# I94100_v1_3 register map
File version: 1.0
Registers are 32-bit, read-write, reset 0x0 unless marked. A register's access mark holds for its fields unless they carry their own. Offsets are from the block's base; [hi:lo] are bit positions; lines under a group give offsets from that group; {n}, {i} and the like mark numbered series; 'fields as' and 'values as' point back to an identical list.

## PWM0 — PWM Register Map
Base 0x40058000
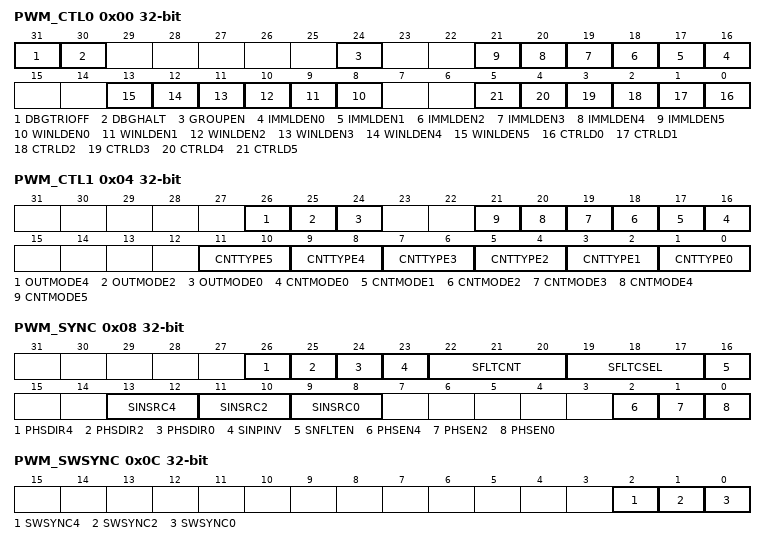
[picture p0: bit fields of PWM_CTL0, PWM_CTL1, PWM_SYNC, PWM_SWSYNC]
0x00 PWM_CTL0 — PWM Control Register 0
  [31] DBGTRIOFF — ICE Debug Mode Acknowledge Disable (Write Protected). PWM pin will keep output no matter ICE debug mode acknowledged or not. Note: This register is write protected. Refer to SYS_REGLCTL register.
    0=ICE debug mode acknowledgement effects PWM output; 1=ICE debug mode acknowledgement disabled
  [30] DBGHALT — ICE Debug Mode Counter Halt (Write Protected). If counter halt is enabled, PWM all counters will keep current value until exit ICE debug mode. Note: This register is write protected. Refer to SYS_REGLCTL register.
    0=ICE debug mode counter halt disable; 1=ICE debug mode counter halt enable
  [24] GROUPEN — Group Function Enable Bit(S)
    0=The output waveform of each PWM channel are independent; 1=Unify the PWM_CH2 and PWM_CH4 to output the same waveform as PWM_CH0 and unify the PWM_CH3 and PWM_CH5 to output the same waveform as PWM_CH1
  [n+16] IMMLDEN{n} (n=0..5) — PWM Channel {n} Immediately Load Enable Bits. Note: If IMMLDEN{n} is enabled, WINLDEN{n} and CTRLD{n} will be invalid.
    0=PERIOD will load to PBUF at the end point of each period. CMPDAT will load to CMPBUF at the end point or center point of each period by setting CTRLD bit; 1=PERIOD/CMPDAT will load to PBUF and CMPBUF immediately when software update PERIOD/CMPDAT
  [n+8] WINLDEN{n} (n=0..5) — PWM Channel {n} Window Load Enable Bits
    0=PERIOD will load to PBUF at the end point of each period. CMPDAT will load to CMPBUF at the end point or center point of each period by setting CTRLD bit; 1=PERIOD will load to PBUF at the end point of each period. CMPDAT will load to CMPBUF at the end point of each period when valid reload window is set. The valid reload window is set by software write 1 to PWM_LOAD register and cleared by hardware after load success
  [n] CTRLD{n} (n=0..5) — PWM Channel {n} Center Re-load. In up-down counter type, PERIOD will load to PBUF at the end point of each period. CMPDAT will load to CMPBUF at the center point of a period.
0x04 PWM_CTL1 — PWM Control Register 1
  [26] OUTMODE4 — PWM Channel 4 Output Mode. Note: When operating in group function, these bits must all set to the same mode.
    0=PWM independent mode; 1=PWM complementary mode
  [25] OUTMODE2 — PWM Channel 2 Output Mode. Note: When operating in group function, these bits must all set to the same mode.
    0=PWM independent mode; 1=PWM complementary mode
  [24] OUTMODE0 — PWM Channel 0 Output Mode. Note: When operating in group function, these bits must all set to the same mode.
    0=PWM independent mode; 1=PWM complementary mode
  [n+16] CNTMODE{n} (n=0..5) — PWM Channel {n} Counter Mode
    0=Auto-reload mode; 1=One-shot mode
  [2n+1:2n] CNTTYPE{n} (n=0..5) — PWM Channel {n} Counter Behavior Type
    0=Up counter type (supports in capture mode); 1=Down count type (supports in capture mode); 2=Up-down counter type; 3=Reserved. Do not use
0x08 PWM_SYNC — PWM Synchronization Register
  [26] PHSDIR4 — PWM Channel 4 Phase Direction Control
    0=Control PWM counter count decrement after synchronizing; 1=Control PWM counter count increment after synchronizing
  [25] PHSDIR2 — PWM Channel 2 Phase Direction Control
    values as PHSDIR4
  [24] PHSDIR0 — PWM Channel 0 Phase Direction Control
    values as PHSDIR4
  [23] SINPINV — SYNC Input Pin Inverse
    0=The state of pin SYNC is passed to the negative edge detector; 1=The inversed state of pin SYNC is passed to the negative edge detector
  [22:20] SFLTCNT — SYNC Edge Detector Filter Count. The register bits control the counter number of edge detector.
  [19:17] SFLTCSEL — SYNC Edge Detector Filter Clock Selection
    0=Filter clock = HCLK; 1=Filter clock = HCLK/2; 2=Filter clock = HCLK/4; 3=Filter clock = HCLK/8; 4=Filter clock = HCLK/16; 5=Filter clock = HCLK/32; 6=Filter clock = HCLK/64; 7=Filter clock = HCLK/128
  [16] SNFLTEN — PWM0_SYNC_IN Noise Filter Enable Bits
    0=Noise filter of input pin PWM0_SYNC_IN is Disabled; 1=Noise filter of input pin PWM0_SYNC_IN is Enabled
  [13:12] SINSRC4 — PWM Channel 4 PWM0_SYNC_IN Source Selection
    0=Synchronize source from SYNC_IN or SWSYNC; 1=Counter equal to 0; 2=Counter equal to PWM_CMPDATm, m denotes 1, 3, 5; 3=SYNC_OUT will not be generated
  [11:10] SINSRC2 — PWM Channel 2 PWM0_SYNC_IN Source Selection
    values as SINSRC4
  [9:8] SINSRC0 — PWM Channel 0 PWM0_SYNC_IN Source Selection
    values as SINSRC4
  [2] PHSEN4 — PWM Channel 4 SYNC Phase Enable Bits
    0=PWM counter disable to load PHS value; 1=PWM counter enable to load PHS value
  [1] PHSEN2 — PWM Channel 2 SYNC Phase Enable Bits
    values as PHSEN4
  [0] PHSEN0 — PWM Channel 0 SYNC Phase Enable Bits
    values as PHSEN4
0x0C PWM_SWSYNC — PWM Software Control Synchronization Register
  [2] SWSYNC4 — PWM Channel 4 Software SYNC Function. When SINSRC4 (PWM_SYNC[13:12]) is selected to 0, SYNC_OUT source is come from SYNC_IN or this bit.
  [1] SWSYNC2 — PWM Channel 2 Software SYNC Function. When SINSRC2 (PWM_SYNC[11:10]) is selected to 0, SYNC_OUT source is come from SYNC_IN or this bit.
  [0] SWSYNC0 — PWM Channel 0 Software SYNC Function. When SINSRC0 (PWM_SYNC[9:8]) is selected to 0, SYNC_OUT source is come from SYNC_IN or this bit.
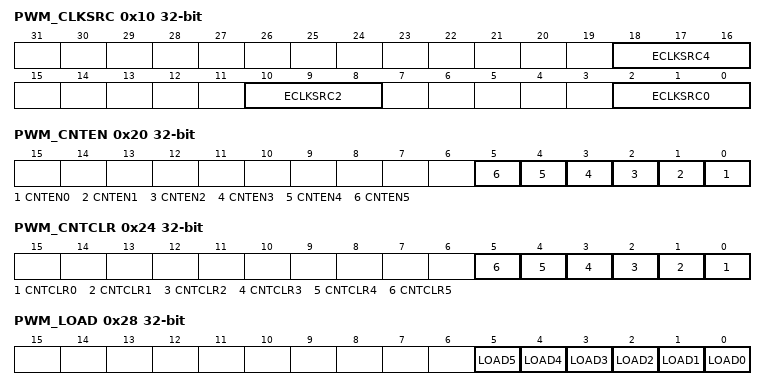
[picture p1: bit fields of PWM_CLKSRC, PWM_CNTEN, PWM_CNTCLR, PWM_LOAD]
0x10 PWM_CLKSRC — PWM Clock Source Register
  [all] fields
    0=PWM0_CLK; {v}=TIMER{v-1} overflow (v=1..4)
  [18:16] ECLKSRC4 — PWM_CH45 External Clock Source Select
  [10:8] ECLKSRC2 — PWM_CH23 External Clock Source Select
  [2:0] ECLKSRC0 — PWM_CH01 External Clock Source Select
0x14 PWM_CLKPSC0_1 — PWM Clock Pre-scale Register 0/1
  [11:0] CLKPSC — PWM Counter Clock Pre-scale. The clock of PWM counter is decided by clock prescaler. Each PWM pair share one PWM counter clock prescaler. The clock of PWM counter is divided by (CLKPSC+ 1).
0x18 PWM_CLKPSC2_3 — PWM Clock Pre-scale Register 2/3
  fields as PWM_CLKPSC0_1
0x1C PWM_CLKPSC4_5 — PWM Clock Pre-scale Register 4/5
  fields as PWM_CLKPSC0_1
0x20 PWM_CNTEN — PWM Counter Enable Register
  [all] fields
    0=PWM Counter and clock prescaler Stop Running; 1=PWM Counter and clock prescaler Start Running
  [n] CNTEN{n} (n=0..5) — PWM Channel {n} Counter Enable Bits
0x24 PWM_CNTCLR — PWM Clear Counter Register
  [all] fields
    0=No effect; 1=Clear 16-bit PWM counter to 0000H
  [n] CNTCLR{n} (n=0..5) — PWM Channel {n} Clear PWM Counter Control Bit. It is automatically cleared by hardware.
0x28 PWM_LOAD
  [all] fields
    0=No effect. No load window is set; 1=Set load window of window loading mode. Load window is set
  [n] LOAD{n} (n=0..5) — PWM Channel {n} Re-load PWM Comparator Register (CMPDAT) Control Bit. This bit is software write, hardware clear when current PWM period end. Write Operation:
{0x30+4i} PWM_PERIOD{i} (i=0..5) — PWM Period Register {i}
  [15:0] PERIOD — PWM Period Register. Up-Count mode: In this mode, PWM counter counts from 0 to PERIOD, and restarts from 0. Down-Count mode: In this mode, PWM counter counts from PERIOD to 0, and restarts from PERIOD.
{0x50+4i} PWM_CMPDAT{i} (i=0..5) — PWM Comparator Register {i}
  [15:0] CMP — PWM Comparator Register. CMP use to compare with CNTR to generate PWM waveform, interrupt and trigger EADC. In independent mode, CMPDAT0~5 denote as 6 independent PWM_CH0~5 compared point. In complementary mode, CMPDAT0, 2, 4 denote as first compared point, and CMPDAT1, 3, 5 denote as second compared point for the corresponding 3 complementary pairs PWM_CH0 and PWM_CH1, PWM_CH2 and PWM_CH3, PWM_CH4 and PWM_CH5.
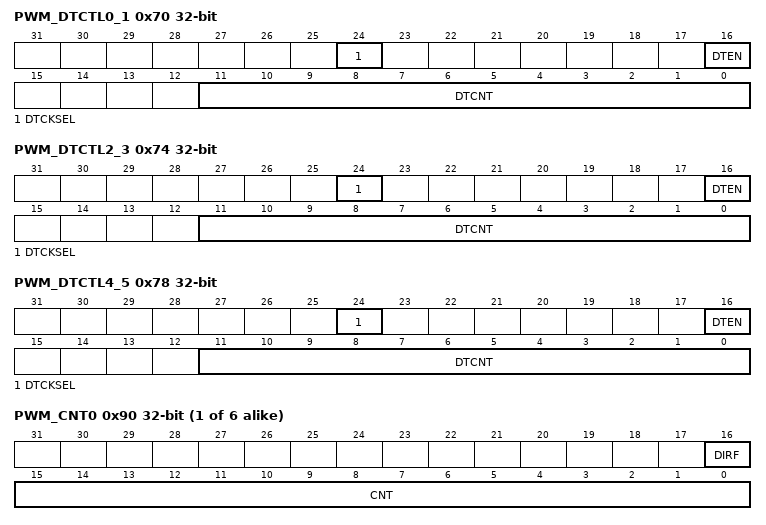
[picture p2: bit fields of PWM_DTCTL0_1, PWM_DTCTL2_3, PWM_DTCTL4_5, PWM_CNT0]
0x70 PWM_DTCTL0_1 — PWM Dead-time Control Register 0/1
  [24] DTCKSEL — Dead-time Clock Select (Write Protected). Note: This register is write protected. Refer to SYS_REGLCTL register.
    0=Dead-time clock source from PWM_CLK; 1=Dead-time clock source from prescaler output
  [16] DTEN — Enable Dead-time Insertion for PWM Pair (PWM_CH0, PWM_CH1) (PWM_CH2, PWM_CH3) (PWM_CH4, PWM_CH5) (Write Protected). Dead-time insertion is only active when this pair of complementary PWM is enabled. If dead- time insertion is inactive, the outputs of pin pair are complementary without any delay. Note: This register is write protected. Refer to SYS_REGLCTL register.
    0=Dead-time insertion Disabled on the pin pair; 1=Dead-time insertion Enabled on the pin pair
  [11:0] DTCNT — Dead-time Counter (Write Protected). The dead-time can be calculated from the following formula: Note: This register is write protected. Refer to SYS_REGLCTL register.
0x74 PWM_DTCTL2_3 — PWM Dead-time Control Register 2/3
  fields as PWM_DTCTL0_1
0x78 PWM_DTCTL4_5 — PWM Dead-time Control Register 4/5
  fields as PWM_DTCTL0_1
0x80 PWM_PHS0_1 — PWM Counter Phase Register 0/1
  [15:0] PHS — PWM Synchronous Start Phase Bits. PHS determines the PWM synchronous start phase value. These bits only use in synchronous function.
0x84 PWM_PHS2_3 — PWM Counter Phase Register 2/3
  fields as PWM_PHS0_1
0x88 PWM_PHS4_5 — PWM Counter Phase Register 4/5
  fields as PWM_PHS0_1
{0x90+4i} PWM_CNT{i} ro (i=0..5) — PWM Counter Register {i}
  [16] DIRF — PWM Direction Indicator Flag (Read Only)
    0=Counter is Down count; 1=Counter is UP count
  [15:0] CNT — PWM Data Register (Read Only). User can monitor CNTR to know the current value in 16-bit period counter.
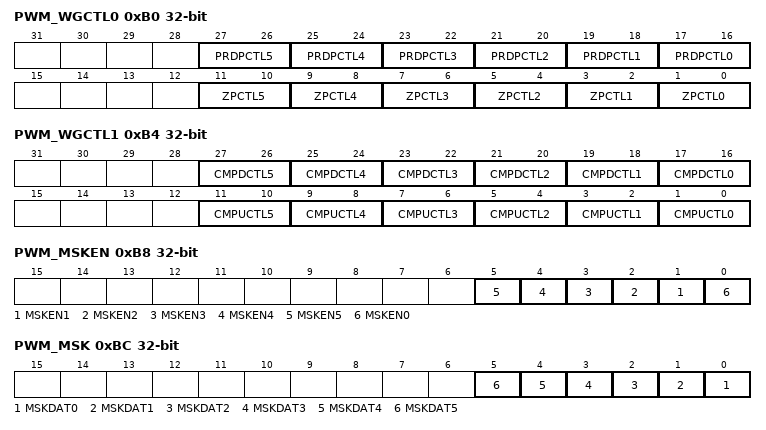
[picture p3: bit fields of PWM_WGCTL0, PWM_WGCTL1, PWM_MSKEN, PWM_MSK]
0xB0 PWM_WGCTL0 — PWM Generation Register 0
  [2n+17:2n+16] PRDPCTL{n} (n=0..5) — PWM Channel {n} Period (Center) Point Control. PWM can control output level when PWM counter count to (PERIODn+1). Note: This bit is center point control when PWM counter operating in up-down counter type.
    0=Do nothing; 1=PWM period (center) point output Low; 2=PWM period (center) point output High; 3=PWM period (center) point output Toggle
  [2n+1:2n] ZPCTL{n} (n=0..5) — PWM Channel {n} Zero Point Control. PWM can control output level when PWM counter count to zero.
    0=Do nothing; 1=PWM zero point output Low; 2=PWM zero point output High; 3=PWM zero point output Toggle
0xB4 PWM_WGCTL1 — PWM Generation Register 1
  [2n+17:2n+16] CMPDCTL{n} (n=0..5) — PWM Channel {n} Compare Down Point Control. PWM can control output level when PWM counter down count to CMPDAT. Note: In complementary mode, CMPDCTL1, 3, 5 use as another CMPDCTL for channel 0, 2, 4.
    0=Do nothing; 1=PWM compare down point output Low; 2=PWM compare down point output High; 3=PWM compare down point output Toggle
  [2n+1:2n] CMPUCTL{n} (n=0..5) — PWM Channel {n} Compare Up Point Control. PWM can control output level when PWM counter up count to CMPDAT. Note: In complementary mode, CMPUCTL1, 3, 5 use as another CMPUCTL for channel 0, 2, 4.
    0=Do nothing; 1=PWM compare up point output Low; 2=PWM compare up point output High; 3=PWM compare up point output Toggle
0xB8 PWM_MSKEN — PWM Mask Enable Register
  [n] MSKEN{n} (n=1..5) — PWM Channel {n} Mask Enable Bits. The PWM output signal will be masked when this bit is enabled and output MSKDAT{n} (PWM_MSK[{n}]) data.
    0=PWM output signal is non-masked; 1=PWM output signal is masked and output MSKDAT{n} (PWM_MSK[{n}]) data
  [0] MSKEN0 — PWM Channel 0 Mask Enable Bits. The PWM output signal will be masked when this bit is enabled.
    0=PWM output signal is non-masked; 1=PWM output signal is masked and output MSKDAT0 (PWM_MSK[0]) data
0xBC PWM_MSK — PWM Mask Data Register
  [n] MSKDAT{n} (n=0..5) — PWM Channel {n} Mask Data Bit. This bit control the state of output pin, if MSKEN{n} (PWM_MSKEN[{n}]) is enabled.
    0=Output logic low to PWM{n}; 1=Output logic high to PWM{n}
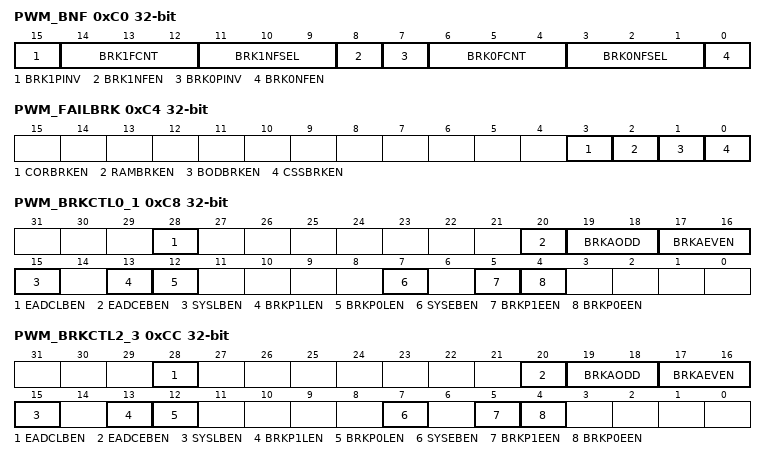
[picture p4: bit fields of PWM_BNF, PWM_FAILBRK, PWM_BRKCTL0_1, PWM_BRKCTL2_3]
0xC0 PWM_BNF — PWM Brake Noise Filter Register
  [15] BRK1PINV — Brake 1 Pin Inverse
    0=The state of pin PWM0_BRAKE1 is passed to the negative edge detector; 1=The inversed state of pin PWM0_BRAKE1 is passed to the negative edge detector
  [14:12] BRK1FCNT — Brake 1 Edge Detector Filter Count. The register bits control the Brake1 filter counter to count from 0 to BRK1FCNT.
  [11:9] BRK1NFSEL — Brake 1 Edge Detector Filter Clock Selection
    values as PWM_SYNC.SFLTCSEL
  [8] BRK1NFEN — PWM Brake 1 Noise Filter Enable Bit
    0=Noise filter of PWM Brake 1 Disabled; 1=Noise filter of PWM Brake 1 Enabled
  [7] BRK0PINV — Brake 0 Pin Inverse
    0=The state of pin PWM0_BRAKE0 is passed to the negative edge detector; 1=The inversed state of pin PWM0_BRAKE1 is passed to the negative edge detector
  [6:4] BRK0FCNT — Brake 0 Edge Detector Filter Count. The register bits control the Brake0 filter counter to count from 0 to BRK1FCNT.
  [3:1] BRK0NFSEL — Brake 0 Edge Detector Filter Clock Selection
    values as PWM_SYNC.SFLTCSEL
  [0] BRK0NFEN — PWM Brake 0 Noise Filter Enable Bit
    0=Noise filter of PWM Brake 0 Disabled; 1=Noise filter of PWM Brake 0 Enabled
0xC4 PWM_FAILBRK — PWM System Fail Brake Control Register
  [3] CORBRKEN — Core Lockup Detection Trigger PWM Brake Function 0 Enable Bit
    0=Brake Function triggered by Core lockup detection Disabled; 1=Brake Function triggered by Core lockup detection Enabled
  [2] RAMBRKEN — SRAM Parity Error Detection Trigger PWM Brake Function 0 Enable Bit
    0=Brake Function triggered by SRAM parity error detection Disabled; 1=Brake Function triggered by SRAM parity error detection Enabled
  [1] BODBRKEN — Brown-out Detection Trigger PWM Brake Function 0 Enable Bit
    0=Brake Function triggered by BOD Disabled; 1=Brake Function triggered by BOD Enabled
  [0] CSSBRKEN — Clock Security System Detection Trigger PWM Brake Function 0 Enable Bit
    0=Brake Function triggered by CSS detection Disabled; 1=Brake Function triggered by CSS detection Enabled
0xC8 PWM_BRKCTL0_1 — PWM Brake Edge Detect Control Register 0/1
  [28] EADCLBEN — Enable EADC Result Monitor (EADCRM) As Level-detect Brake Source (Write Protected). Note: This register is write protected. Refer to SYS_REGLCTL register.
    0=EADCRM as level-detect brake source Disabled; 1=EADCRM as level-detect brake source Enabled
  [20] EADCEBEN — Enable ADC Result Monitor (EADCRM) As Edge-detect Brake Source (Write Protected). Note: This register is write protected. Refer to SYS_REGLCTL register.
    0=EADCRM as edge-detect brake source Disabled; 1=EADCRM as edge-detect brake source Enabled
  [19:18] BRKAODD — PWM Brake Action Select for Odd Channel (Write Protected). Note: This register is write protected. Refer to SYS_REGLCTL register.
    0=PWM0 brake event will not affect odd channels output; 1=PWM odd channel output tri-state when PWM0 brake event happened; 2=PWM odd channel output low level when PWM0 brake event happened; 3=PWM odd channel output high level when PWM0 brake event happened
  [17:16] BRKAEVEN — PWM Brake Action Select for Even Channel (Write Protected). Note: This register is write protected. Refer to SYS_REGLCTL register.
    0=PWM0 brake event will not affect even channels output; 1=PWM even channel output tri-state when PWM0 brake event happened; 2=PWM even channel output low level when PWM0 brake event happened; 3=PWM even channel output high level when PWM0 brake event happened
  [15] SYSLBEN — Enable System Fail As Level-detect Brake Source (Write Protected). Note: This register is write protected. Refer to SYS_REGLCTL register.
    0=System Fail condition as level-detect brake source Disabled; 1=System Fail condition as level-detect brake source Enabled
  [13] BRKP1LEN — Enable BKP1 Pin As Level-detect Brake Source (Write Protected). Note: This register is write protected. Refer to SYS_REGLCTL register.
    0=PWM0_BRAKE1 pin as level-detect brake source Disabled; 1=PWM0_BRAKE1 pin as level-detect brake source Enabled
  [12] BRKP0LEN — Enable BKP0 Pin As Level-detect Brake Source (Write Protected). Note: This register is write protected. Refer to SYS_REGLCTL register.
    0=PWM0_BRAKE0 pin as level-detect brake source Disabled; 1=PWM0_BRAKE0 pin as level-detect brake source Enabled
  [7] SYSEBEN — Enable System Fail As Edge-detect Brake Source (Write Protected). Note: This register is write protected. Refer to SYS_REGLCTL register.
    0=System Fail condition as edge-detect brake source Disabled; 1=System Fail condition as edge-detect brake source Enabled
  [5] BRKP1EEN — Enable PWM0_BRAKE1 Pin As Edge-detect Brake Source (Write Protected). Note: This register is write protected. Refer to SYS_REGLCTL register.
    0=PWM0_BRAKE1 pin as edge-detect brake source Disabled; 1=PWM0_BRAKE1 pin as edge-detect brake source Enabled
  [4] BRKP0EEN — Enable PWM0_BRAKE0 Pin As Edge-detect Brake Source (Write Protected). Note: This register is write protected. Refer to SYS_REGLCTL register.
    0=PWM0_BRAKE0 pin as edge-detect brake source Disabled; 1=PWM0_BRAKE0 pin as edge-detect brake source Enabled
0xCC PWM_BRKCTL2_3 — PWM Brake Edge Detect Control Register 2/3
  fields as PWM_BRKCTL0_1
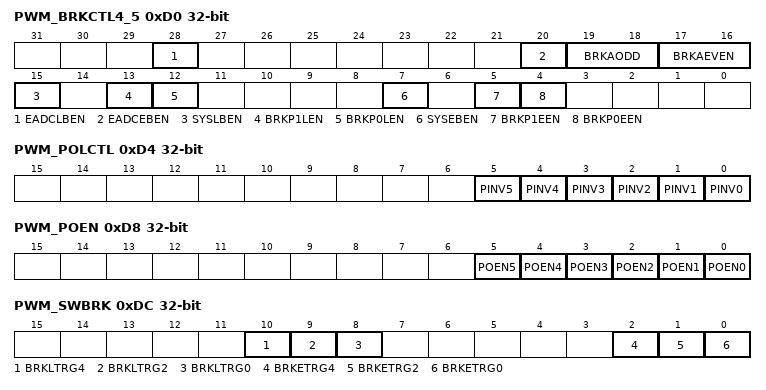
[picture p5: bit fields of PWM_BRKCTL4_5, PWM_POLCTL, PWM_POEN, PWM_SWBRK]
0xD0 PWM_BRKCTL4_5 — PWM Brake Edge Detect Control Register 4/5
  fields as PWM_BRKCTL0_1
0xD4 PWM_POLCTL — PWM Pin Polar Inverse Register
  [all] fields
    0=PWM output polar inverse Disabled; 1=PWM output polar inverse Enabled
  [n] PINV{n} (n=0..5) — PWM Channel {n} PIN Polar Inverse Control. The register controls polarity state of PWM output.
0xD8 PWM_POEN — PWM Output Enable Register
  [all] fields
    0=PWM pin at tri-state; 1=PWM pin in output mode
  [n] POEN{n} (n=0..5) — PWM Channel {n} Pin Output Enable Bits
0xDC PWM_SWBRK wo — PWM Software Brake Control Register
  [10] BRKLTRG4 — PWM Pair 4 Level Brake Software Trigger (Write Only) (Write Protected). Write 1 to this bit will trigger level brake, and set BRKLIF4 to 1 in PWM_INTSTS1 register. Note: This register is write protected. Refer to SYS_REGLCTL register.
  [9] BRKLTRG2 — PWM Pair 2 Level Brake Software Trigger (Write Only) (Write Protected). Write 1 to this bit will trigger level brake, and set BRKLIF2 to 1 in PWM_INTSTS1 register. Note: This register is write protected. Refer to SYS_REGLCTL register.
  [8] BRKLTRG0 — PWM Pair 0 Level Brake Software Trigger (Write Only) (Write Protected). Write 1 to this bit will trigger level brake, and set BRKLIF0 to 1 in PWM_INTSTS1 register. Note: This register is write protected. Refer to SYS_REGLCTL register.
  [2] BRKETRG4 — PWM Pair 4 Edge Brake Software Trigger (Write Only) (Write Protected). Write 1 to this bit will trigger edge brake, and set BRKEIF4 to 1 in PWM_INTSTS1 register. Note: This register is write protected. Refer to SYS_REGLCTL register.
  [1] BRKETRG2 — PWM Pair 2 Edge Brake Software Trigger (Write Only) (Write Protected). Write 1 to this bit will trigger edge brake, and set BRKEIF2 to 1 in PWM_INTSTS1 register. Note: This register is write protected. Refer to SYS_REGLCTL register.
  [0] BRKETRG0 — PWM Pair 0 Edge Brake Software Trigger (Write Only) (Write Protected). Write 1 to this bit will trigger edge brake, and set BRKEIF0 to 1 in PWM_INTSTS1 register. Note: This register is write protected. Refer to SYS_REGLCTL register.
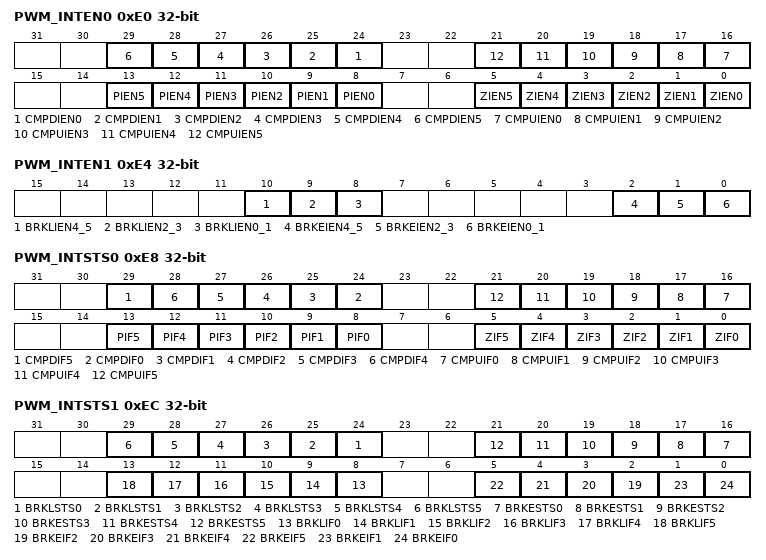
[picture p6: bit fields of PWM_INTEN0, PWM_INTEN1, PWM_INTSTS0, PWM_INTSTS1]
0xE0 PWM_INTEN0 — PWM Interrupt Enable Register 0
  [n+24] CMPDIEN{n} (n=0..5) — PWM Channel {n} Compare Down Count Interrupt Enable Bits. Note: In complementary mode, CMPDIEN1, 3, 5 use as another CMPDIEN for channel 0, 2, 4.
    0=Compare down count interrupt Disabled; 1=Compare down count interrupt Enabled
  [n+16] CMPUIEN{n} (n=0..5) — PWM Channel {n} Compare Up Count Interrupt Enable Bits. Note: In complementary mode, CMPUIEN1, 3, 5 use as another CMPUIEN for channel 0, 2, 4.
    0=Compare up count interrupt Disabled; 1=Compare up count interrupt Enabled
  [13] PIEN5 — PWM Channel 5 Period Point Interrupt Enable Bits. Note1: When up-down counter type period point means center point. Note2: This channels will read always 0 at complementary mode.
    0=Period point interrupt Disabled; 1=Period point interrupt Enabled
  [12] PIEN4 — PWM Channel 4 Period Point Interrupt Enable Bits. Note: When up-down counter type period point means center point.
    values as PIEN5
  [11] PIEN3 — PWM Channel 3 Period Point Interrupt Enable Bits. Note1: When up-down counter type period point means center point. Note2: This channels will read always 0 at complementary mode.
    values as PIEN5
  [10] PIEN2 — PWM Channel 2 Period Point Interrupt Enable Bits. Note: When up-down counter type period point means center point.
    values as PIEN5
  [9] PIEN1 — PWM Channel 1 Period Point Interrupt Enable Bits. Note1: When up-down counter type period point means center point. Note2: This channels will read always 0 at complementary mode.
    values as PIEN5
  [8] PIEN0 — PWM Channel 0 Period Point Interrupt Enable Bits. Note: When up-down counter type period point means center point.
    values as PIEN5
  [5] ZIEN5 — PWM Channel 5 Zero Point Interrupt Enable Bits. Note: This channel will read always 0 at complementary mode.
    0=Zero point interrupt Disabled; 1=Zero point interrupt Enabled
  [4] ZIEN4 — PWM Channel 4 Zero Point Interrupt Enable Bits
    values as ZIEN5
  [3] ZIEN3 — PWM Channel 3 Zero Point Interrupt Enable Bits. Note: This channel will read always 0 at complementary mode.
    values as ZIEN5
  [2] ZIEN2 — PWM Channel 2 Zero Point Interrupt Enable Bits
    values as ZIEN5
  [1] ZIEN1 — PWM Channel 1 Zero Point Interrupt Enable Bits. Note: This channel will read always 0 at complementary mode.
    values as ZIEN5
  [0] ZIEN0 — PWM Channel 0 Zero Point Interrupt Enable Bits
    values as ZIEN5
0xE4 PWM_INTEN1 — PWM Interrupt Enable Register 1
  [10] BRKLIEN4_5 — PWM Level-detect Brake Interrupt Enable for Channel4/5 (Write Protected). Note: This register is write protected. Refer to SYS_REGLCTL register.
    0=Level-detect Brake interrupt for channel4/5 Disabled; 1=Level-detect Brake interrupt for channel4/5 Enabled
  [9] BRKLIEN2_3 — PWM Level-detect Brake Interrupt Enable for Channel2/3 (Write Protected). Note: This register is write protected. Refer to SYS_REGLCTL register.
    0=Level-detect Brake interrupt for channel2/3 Disabled; 1=Level-detect Brake interrupt for channel2/3 Enabled
  [8] BRKLIEN0_1 — PWM Level-detect Brake Interrupt Enable for Channel0/1 (Write Protected). Note: This register is write protected. Refer to SYS_REGLCTL register.
    0=Level-detect Brake interrupt for channel0/1 Disabled; 1=Level-detect Brake interrupt for channel0/1 Enabled
  [2] BRKEIEN4_5 — PWM Edge-detect Brake Interrupt Enable for Channel4/5 (Write Protected). Note: This register is write protected. Refer to SYS_REGLCTL register.
    0=Edge-detect Brake interrupt for channel4/5 Disabled; 1=Edge-detect Brake interrupt for channel4/5 Enabled
  [1] BRKEIEN2_3 — PWM Edge-detect Brake Interrupt Enable for Channel2/3 (Write Protected). Note: This register is write protected. Refer to SYS_REGLCTL register.
    0=Edge-detect Brake interrupt for channel2/3 Disabled; 1=Edge-detect Brake interrupt for channel2/3 Enabled
  [0] BRKEIEN0_1 — PWM Edge-detect Brake Interrupt Enable for Channel0/1 (Write Protected). Note: This register is write protected. Refer to SYS_REGLCTL register.
    0=Edge-detect Brake interrupt for channel0/1 Disabled; 1=Edge-detect Brake interrupt for channel0/1 Enabled
0xE8 PWM_INTSTS0 — PWM Interrupt Flag Register 0
  [29] CMPDIF5 — PWM Channel 4 Compare Down Count Interrupt Flag. Flag is set by hardware when PWM counter down count and reaches PWM_CMPDAT5, software can clear this bit by writing 1 to it. Note1: If CMPDAT equal to PERIOD, this flag is not working in down counter type selection. Note2: In complementary mode, CMPDIF1, 3, 5 use as another CMPDIF for channel 0, 2, 4.
  [n+24] CMPDIF{n} (n=0..4) — PWM Channel {n} Compare Down Count Interrupt Flag. Flag is set by hardware when PWM counter down count and reaches PWM_CMPDAT{n}, software can clear this bit by writing 1 to it. Note1: If CMPDAT equal to PERIOD, this flag is not working in down counter type selection. Note2: In complementary mode, CMPDIF1, 3, 5 use as another CMPDIF for channel 0, 2, 4.
  [n+16] CMPUIF{n} (n=0..5) — PWM Channel {n} Compare Up Count Interrupt Flag. Flag is set by hardware when PWM counter up count and reaches PWM_CMPDAT{n}, software can clear this bit by writing 1 to it. Note1: If CMPDAT equal to PERIOD, this flag is not working in up counter type selection. Note2: In complementary mode, CMPUIF1, 3, 5 use as another CMPUIF for channel 0, 2, 4.
  [n+8] PIF{n} (n=1..5) — PWM Channel {n} Period Point Interrupt Flag. This bit is set by hardware when PWM counter reaches PWM_PERIOD{n}, software can write 1 to clear this bit to zero.
  [8] PIF0 — PWM Channel 0 Period Point Interrupt Flag. This bit is set by hardware when PWM counter reaches PWM_PERIOD0, software can write 1 to clear this bit to zero..
  [n] ZIF{n} (n=0..5) — PWM Channel {n} Zero Point Interrupt Flag. This bit is set by hardware when PWM counter reaches zero, software can write 1 to clear this bit to zero.
0xEC PWM_INTSTS1 — PWM Interrupt Flag Register 1
  [n+24] BRKLSTS{n} ro (n=0..5) — PWM Channel {n} Level-detect Brake Status (Read Only). Note: This bit is read only and auto cleared by hardware. When enabled brake source return to high level, PWM will release brake state until current PWM period finished. The PWM waveform will start output from next full PWM period.
    0=PWM channel {n} level-detect brake state is released; 1=When PWM channel {n} level-detect brake detects a falling edge of any enabled brake source; this flag will be set to indicate the PWM channel {n} at brake state
  [n+16] BRKESTS{n} (n=0..5) — PWM Channel {n} Edge-detect Brake Status
    0=PWM channel {n} edge-detect brake state is released; 1=When PWM channel {n} edge-detect brake detects a falling edge of any enabled brake source; this flag will be set to indicate the PWM channel {n} at brake state, writing 1 to clear
  [n+8] BRKLIF{n} (n=0..5) — PWM Channel {n} Level-detect Brake Interrupt Flag (Write Protected). Note: This register is write protected. Refer to SYS_REGLCTL register.
    0=PWM channel {n} level-detect brake event do not happened; 1=When PWM channel {n} level-detect brake event happened, this bit is set to 1, writing 1 to clear
  [n] BRKEIF{n} (n=2..5) — PWM Channel {n} Edge-detect Brake Interrupt Flag (Write Protected). Note: This register is write protected. Refer to SYS_REGLCTL register.
    0=PWM channel {n} edge-detect brake event do not happened; 1=When PWM channel {n} edge-detect brake event happened, this bit is set to 1, writing 1 to clear
  [1] BRKEIF1 — PWM Channel 1 Edge-detect Brake Interrupt Flag (Write Protected). Note: This register is write protected. Refer to SYS_REGLCTL register.
    0=PWM channel 1 edge-detect brake event do not happened; 1=When PWM channel1 edge-detect brake event happened, this bit is set to 1, writing 1 to clear
  [0] BRKEIF0 — PWM Channel 0 Edge-detect Brake Interrupt Flag (Write Protected). Note: This register is write protected. Refer to SYS_REGLCTL register.
    0=PWM channel 0 edge-detect brake event do not happened; 1=When PWM channel0 edge-detect brake event happened, this bit is set to 1, writing 1 to clear
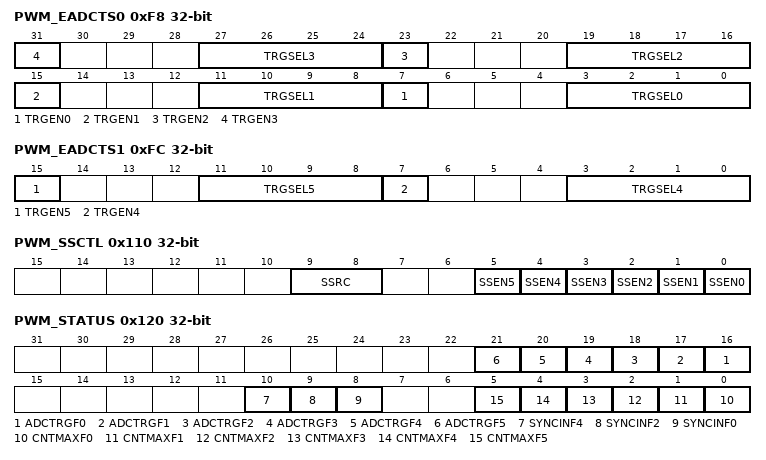
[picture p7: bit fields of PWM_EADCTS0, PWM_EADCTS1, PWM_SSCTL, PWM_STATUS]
0xF8 PWM_EADCTS0 — PWM Trigger EADC Source Select Register 0
  [8n+7] TRGEN{n} (n=0..3) — PWM_CH{n} Trigger EADC enable bit
  [27:24] TRGSEL3 — PWM_CH3 Trigger EADC Source Select
    0=PWM_CH2 zero point; 1=PWM_CH2 period point; 2=PWM_CH2 zero or period point; 3=PWM_CH2 up-count CMPDAT point; 4=PWM_CH2 down-count CMPDAT point; 5=PWM_CH3 zero point; 6=PWM_CH3 period point; 7=PWM_CH3 zero or period point; 8=PWM_CH3 up-count CMPDAT point; 9=PWM_CH3 down-count CMPDAT point; 10=PWM_CH0 up-count free CMPDAT point; 11=PWM_CH0 down-count free CMPDAT point; 12=PWM_CH2 up-count free CMPDAT point; 13=PWM_CH2 down-count free CMPDAT point; 14=PWM_CH4 up-count free CMPDAT point; 15=PWM_CH4 down-count free CMPDAT point
  [19:16] TRGSEL2 — PWM_CH2 Trigger EADC Source Select
    values as TRGSEL3
  [11:8] TRGSEL1 — PWM_CH1 Trigger EADC Source Select
    0=PWM_CH0 zero point; 1=PWM_CH0 period point; 2=PWM_CH0 zero or period point; 3=PWM_CH0 up-count CMPDAT point; 4=PWM_CH0 down-count CMPDAT point; 5=PWM_CH1 zero point; 6=PWM_CH1 period point; 7=PWM_CH1 zero or period point; 8=PWM_CH1 up-count CMPDAT point; 9=PWM_CH1 down-count CMPDAT point; 10=PWM_CH0 up-count free CMPDAT point; 11=PWM_CH0 down-count free CMPDAT point; 12=PWM_CH2 up-count free CMPDAT point; 13=PWM_CH2 down-count free CMPDAT point; 14=PWM_CH4 up-count free CMPDAT point; 15=PWM_CH4 down-count free CMPDAT point
  [3:0] TRGSEL0 — PWM_CH0 Trigger EADC Source Select
    values as TRGSEL1
0xFC PWM_EADCTS1 — PWM Trigger EADC Source Select Register 1
  [15] TRGEN5 — PWM_CH5 Trigger EADC enable bit
  [11:8] TRGSEL5 — PWM_CH5 Trigger EADC Source Select
    0=PWM_CH4 zero point; 1=PWM_CH4 period point; 2=PWM_CH4 zero or period point; 3=PWM_CH4 up-count CMPDAT point; 4=PWM_CH4 down-count CMPDAT point; 5=PWM_CH5 zero point; 6=PWM_CH5 period point; 7=PWM_CH5 zero or period point; 8=PWM_CH5 up-count CMPDAT point; 9=PWM_CH5 down-count CMPDAT point; 10=PWM_CH0 up-count free CMPDAT point; 11=PWM_CH0 down-count free CMPDAT point; 12=PWM_CH2 up-count free CMPDAT point; 13=PWM_CH2 down-count free CMPDAT point; 14=PWM_CH4 up-count free CMPDAT point; 15=PWM_CH4 down-count free CMPDAT point
  [7] TRGEN4 — PWM_CH4 Trigger EADC enable bit
  [3:0] TRGSEL4 — PWM_CH4 Trigger EADC Source Select
    values as TRGSEL5
0x100 PWM_FTCMPDAT0_1 — PWM Free Trigger Compare Register 0/1
  [15:0] FTCMP — PWM Free Trigger Compare Register. FTCMP use to compare with even CNTR to trigger EADC. FTCMPDAT0_1, 2_3, 4_5 corresponding complementary pairs PWM_CH0 and PWM_CH1, PWM_CH2 and PWM_CH3, PWM_CH4 and PWM_CH5.
0x104 PWM_FTCMPDAT2_3 — PWM Free Trigger Compare Register 2/3
  fields as PWM_FTCMPDAT0_1
0x108 PWM_FTCMPDAT4_5 — PWM Free Trigger Compare Register 4/5
  fields as PWM_FTCMPDAT0_1
0x110 PWM_SSCTL — PWM Synchronous Start Control Register
  [9:8] SSRC — PWM Synchronous Start Source Select Bits
    0=Synchronous start source come from PWM0
  [n] SSEN{n} (n=0..5) — PWM Channel {n} Synchronous Start Function Enable Bits. When synchronous start function is enabled, the PWM counter enable register (PWM_CNTEN) can be enabled by writing PWM synchronous start trigger bit (CNTSEN).
    0=PWM synchronous start function Disabled; 1=PWM synchronous start function Enabled
0x114 PWM_SSTRG wo — PWM Synchronous Start Trigger Register
  [0] CNTSEN — PWM Counter Synchronous Start Enable (Write Only). PMW counter synchronous enable function is used to make selected PWM channels (include PWM0_CHx) start counting at the same time. Writing this bit to 1 will also set the counter enable bit (CNTENn, n denotes channel 0 to 5) if correlated PWM channel counter synchronous start function is enabled.
0x120 PWM_STATUS
  [n+16] ADCTRGF{n} (n=0..5) — PWM Channel {n} EADC Start of Conversion Flag
    0=Indicates no EADC start of conversion trigger event has occurred; 1=Indicates an EADC start of conversion trigger event has occurred, software can write 1 to clear this bit
  [10] SYNCINF4 — PWM Channel 4 Input Synchronization Latched Flag
    0=Indicates no SYNC_IN event has occurred; 1=Indicates an SYNC_IN event has occurred, software can write 1 to clear this bit
  [9] SYNCINF2 — PWM Channel 2 Input Synchronization Latched Flag
    values as SYNCINF4
  [8] SYNCINF0 — PWM Channel 0 Input Synchronization Latched Flag
    values as SYNCINF4
  [n] CNTMAXF{n} (n=0..5) — PWM Channel {n} Time-base Counter Equal to 0xFFFF Latched Flag
    0=indicates the time-base counter never reached its maximum value 0xFFFF; 1=indicates the time-base counter reached its maximum value, software can write 1 to clear this bit
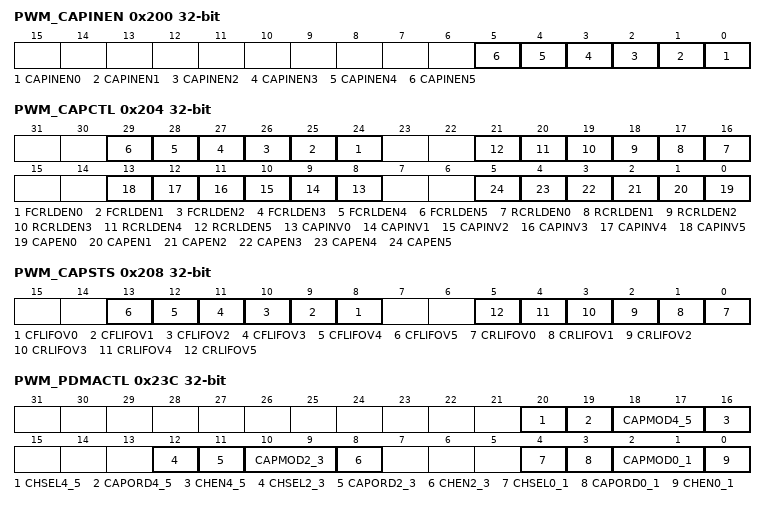
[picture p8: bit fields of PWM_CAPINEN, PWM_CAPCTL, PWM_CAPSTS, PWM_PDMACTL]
0x200 PWM_CAPINEN — PWM Capture Input Enable Register
  [all] fields
    0=PWM Channel capture input path Disabled. The input of PWM channel capture function is always regarded as 0; 1=PWM Channel capture input path Enabled. The input of PWM channel capture function comes from correlative multifunction pin
  [n] CAPINEN{n} (n=0..5) — PWM Channel {n} Capture Input Enable Bits
0x204 PWM_CAPCTL — PWM Capture Control Register
  [n+24] FCRLDEN{n} (n=0..5) — PWM Channel {n} Falling Capture Reload Enable Bits
    0=Falling capture reload counter Disabled; 1=Falling capture reload counter Enabled
  [n+16] RCRLDEN{n} (n=0..5) — PWM Channel {n} Rising Capture Reload Enable Bits
    0=Rising capture reload counter Disabled; 1=Rising capture reload counter Enabled
  [n+8] CAPINV{n} (n=0..5) — PWM Channel {n} Capture Inverter Enable Bits
    0=Capture source inverter Disabled; 1=Capture source inverter Enabled. Reverse the input signal from GPIO
  [n] CAPEN{n} (n=0..5) — PWM Channel {n} Capture Function Enable Bits
    0=Capture function Disabled. RCAPDAT/FCAPDAT register will not be updated; 1=Capture function Enabled. Capture latched the PWM counter value when detected rising or falling edge of input signal and saved to RCAPDAT (Rising latch) and FCAPDAT (Falling latch)
0x208 PWM_CAPSTS ro — PWM Capture Status Register
  [n+8] CFLIFOV{n} (n=0..5) — PWM Channel {n} Capture Falling Latch Interrupt Flag Overrun Status (Read Only). This flag indicates if falling latch happened when the corresponding CFLIF is 1. Note: This bit will be cleared automatically when user clear corresponding CFLIF.
  [n] CRLIFOV{n} (n=0..5) — PWM Channel {n} Capture Rising Latch Interrupt Flag Overrun Status (Read Only). This flag indicates if rising latch happened when the corresponding CRLIF is 1. Note: This bit will be cleared automatically when user clear corresponding CRLIF.
{0x20C+8i} PWM_RCAPDAT{i} ro (i=0..5) — PWM Rising Capture Data Register {i}
  [15:0] RCAPDAT — PWM Rising Capture Data Register (Read Only). When rising capture condition happened, the PWM counter value will be saved in this register.
{0x210+8i} PWM_FCAPDAT{i} ro (i=0..5) — PWM Falling Capture Data Register {i}
  [15:0] FCAPDAT — PWM Falling Capture Data Register (Read Only). When falling capture condition happened, the PWM counter value will be saved in this register.
0x23C PWM_PDMACTL — PWM PDMA Control Register
  [20] CHSEL4_5 — Select Channel 4/5 to Do PDMA Transfer
    0=Channel4; 1=Channel5
  [19] CAPORD4_5 — Capture Channel 4/5 Rising/Falling Order
    0=PWM_FCAPDAT4/5 is the first captured data to memory; 1=PWM_RCAPDAT4/5 is the first captured data to memory
  [18:17] CAPMOD4_5 — Select PWM_RCAPDAT4/5 or PWM_FCAPDAT4/5 to Do PDMA Transfer
    0=Reserved. Do not use; 1=PWM_RCAPDAT4/5; 2=PWM_FCAPDAT4/5; 3=Both PWM_RCAPDAT4/5 and PWM_FCAPDAT4/5
  [16] CHEN4_5 — Channel 4/5 PDMA Enable
    0=Channel 4/5 PDMA function Disabled; 1=Channel 4/5 PDMA function Enabled for the channel 4/5 captured data and transfer to memory
  [12] CHSEL2_3 — Select Channel 2/3 to Do PDMA Transfer
    0=Channel2; 1=Channel3
  [11] CAPORD2_3 — Capture Channel 2/3 Rising/Falling Order
    0=PWM_FCAPDAT2/3 is the first captured data to memory; 1=PWM_RCAPDAT2/3 is the first captured data to memory
  [10:9] CAPMOD2_3 — Select PWM_RCAPDAT2/3 or PWM_FCAODAT2/3 to Do PDMA Transfer
    0=Reserved. Do not use; 1=PWM_RCAPDAT2/3; 2=PWM_FCAPDAT2/3; 3=Both PWM_RCAPDAT2/3 and PWM_FCAPDAT2/3
  [8] CHEN2_3 — Channel 2/3 PDMA Enable
    0=Channel 2/3 PDMA function Disabled; 1=Channel 2/3 PDMA function Enabled for the channel 2/3 captured data and transfer to memory
  [4] CHSEL0_1 — Select Channel 0/1 to Do PDMA Transfer
    0=Channel0; 1=Channel1
  [3] CAPORD0_1 — Capture Channel 0/1 Rising/Falling Order
    0=PWM_FCAPDAT0/1 is the first captured data to memory; 1=PWM_RCAPDAT0/1 is the first captured data to memory
  [2:1] CAPMOD0_1 — Select PWM_RCAPDAT0/1 or PWM_FCAPDAT0/1 to Do PDMA Transfer
    0=Reserved. Do not use; 1=PWM_RCAPDAT0/1; 2=PWM_FCAPDAT0/1; 3=Both PWM_RCAPDAT0/1 and PWM_FCAPDAT0/1
  [0] CHEN0_1 — Channel 0/1 PDMA Enable
    0=Channel 0/1 PDMA function Disabled; 1=Channel 0/1 PDMA function Enabled for the channel 0/1 captured data and transfer to memory
0x240 PWM_PDMACAP0_1 ro — PWM Capture Channel 01 PDMA Register
  [15:0] CAPBUF — PWM Capture PDMA Register (Read Only). This register is use as a buffer to transfer PWM capture rising or falling data to memory by PDMA.
0x244 PWM_PDMACAP2_3 ro — PWM Capture Channel 23 PDMA Register
  fields as PWM_PDMACAP0_1
0x248 PWM_PDMACAP4_5 ro — PWM Capture Channel 45 PDMA Register
  fields as PWM_PDMACAP0_1
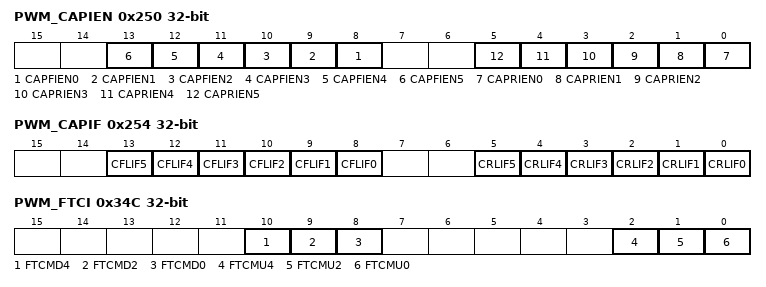
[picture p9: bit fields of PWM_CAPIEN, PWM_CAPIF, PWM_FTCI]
0x250 PWM_CAPIEN — PWM Capture Interrupt Enable Register
  [n+8] CAPFIEN{n} (n=0..5) — PWM Channel {n} Capture Falling Latch Interrupt Enable Bits. Note: When Capture with PDMA operating, CINTENR corresponding channel CAPFIEN must be disabled.
    0=Capture falling edge latch interrupt Disabled; 1=Capture falling edge latch interrupt Enabled
  [n] CAPRIEN{n} (n=0..5) — PWM Channel {n} Capture Rising Latch Interrupt Enable Bits. Note: When Capture with PDMA operating, CINTENR corresponding channel CAPRIEN must be disabled.
    0=Capture rising edge latch interrupt Disabled; 1=Capture rising edge latch interrupt Enabled
0x254 PWM_CAPIF — PWM Capture Interrupt Flag Register
  [n+8] CFLIF{n} (n=0..5) — PWM Channel {n} Capture Falling Latch Interrupt Flag. This bit is writing 1 to clear. Note: When Capture with PDMA operating, CAPIF corresponding channel CFLIF will cleared by hardware after PDMA transfer data.
    0=No capture falling latch condition happened; 1=Capture falling latch condition happened, this flag will be set to high
  [n] CRLIF{n} (n=0..5) — PWM Channel {n} Capture Rising Latch Interrupt Flag. This bit is writing 1 to clear. Note: When Capture with PDMA operating, CAPIF corresponding channel CRLIF will cleared by hardware after PDMA transfer data.
    0=No capture rising latch condition happened; 1=Capture rising latch condition happened, this flag will be set to high
{0x304+4i} PWM_PBUF{i} ro (i=0..5) — PWM PERIOD{i} Buffer
  [15:0] PBUF — PWM Period Register Buffer (Read Only). Used as PERIOD active register.
{0x31C+4i} PWM_CMPBUF{i} ro (i=0..5) — PWM CMPDAT{i} Buffer
  [15:0] CMPBUF — PWM Comparator Register Buffer (Read Only). Used as CMP active register.
0x334 PWM_CPSCBUF0_1 ro — PWM CLKPSC0_1 Buffer
  [11:0] CPSCBUF — PWM Counter Clock Pre-scale Buffer. Use as PWM counter clock pre-scare active register.
0x338 PWM_CPSCBUF2_3 ro — PWM CLKPSC2_3 Buffer
  fields as PWM_CPSCBUF0_1
0x33C PWM_CPSCBUF4_5 ro — PWM CLKPSC4_5 Buffer
  fields as PWM_CPSCBUF0_1
0x340 PWM_FTCBUF0_1 ro — PWM FTCMPDAT0_1 Buffer
  [15:0] FTCMPBUF — PWM FTCMPDAT Buffer (Read Only). Used as FTCMPDAT active register.
0x344 PWM_FTCBUF2_3 ro — PWM FTCMPDAT2_3 Buffer
  fields as PWM_FTCBUF0_1
0x348 PWM_FTCBUF4_5 ro — PWM FTCMPDAT4_5 Buffer
  fields as PWM_FTCBUF0_1
0x34C PWM_FTCI — PWM FTCMPDAT Indicator Register
  [10] FTCMD4 — PWM Channel 4 FTCMPDAT Down Indicator
  [9] FTCMD2 — PWM Channel 2 FTCMPDAT Down Indicator
  [8] FTCMD0 — PWM Channel 0 FTCMPDAT Down Indicator
  [2] FTCMU4 — PWM Channel 4 FTCMPDAT Up Indicator
  [1] FTCMU2 — PWM Channel 2 FTCMPDAT Up Indicator
  [0] FTCMU0 — PWM Channel 0 FTCMPDAT Up Indicator
